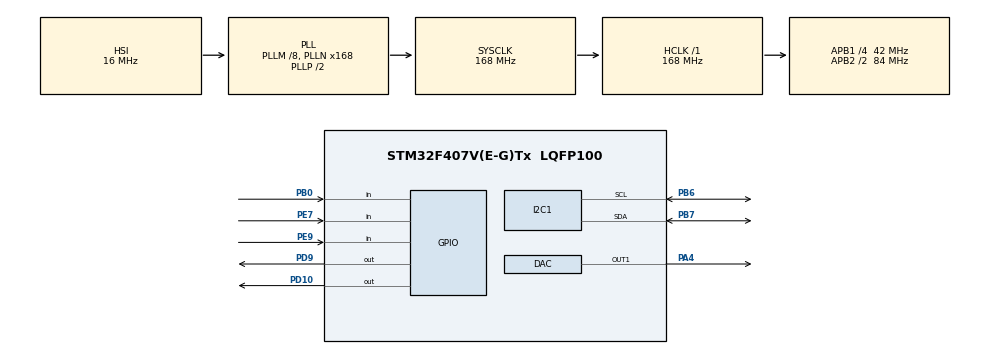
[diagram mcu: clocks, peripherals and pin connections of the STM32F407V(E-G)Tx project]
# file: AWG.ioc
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DAC.DAC_Trigger=DAC_TRIGGER_T2_TRGO
Dma.DAC1.0.Direction=DMA_MEMORY_TO_PERIPH
Dma.DAC1.0.FIFOMode=DMA_FIFOMODE_DISABLE
Dma.DAC1.0.Instance=DMA1_Stream5
Dma.DAC1.0.MemDataAlignment=DMA_MDATAALIGN_HALFWORD
Dma.DAC1.0.MemInc=DMA_MINC_ENABLE
Dma.DAC1.0.Mode=DMA_CIRCULAR
Dma.DAC1.0.PeriphDataAlignment=DMA_PDATAALIGN_HALFWORD
Dma.DAC1.0.PeriphInc=DMA_PINC_DISABLE
Dma.DAC1.0.Priority=DMA_PRIORITY_LOW
Dma.Request0=DAC1
Mcu.Family=STM32F4
Mcu.Name=STM32F407V(E-G)Tx
Mcu.Package=LQFP100
NVIC.DMA1_Stream5_IRQn=true\:0\:0\:false\:false\:true\:false\:true\:true
NVIC.PriorityGroup=NVIC_PRIORITYGROUP_4
PA4.Signal=COMP_DAC1_group
PB0.GPIO_PuPd=GPIO_PULLUP
PB0.Signal=GPIO_Input
PB6.Mode=I2C
PB6.Signal=I2C1_SCL
PB7.Mode=I2C
PB7.Signal=I2C1_SDA
PC14-OSC32_IN.Mode=LSE-External-Oscillator
PC14-OSC32_IN.Signal=RCC_OSC32_IN
PC15-OSC32_OUT.Mode=LSE-External-Oscillator
PC15-OSC32_OUT.Signal=RCC_OSC32_OUT
PD10.GPIO_ModeDefaultOutputPP=GPIO_MODE_OUTPUT_OD
PD10.GPIO_PuPd=GPIO_PULLUP
PD10.Signal=GPIO_Output
PD9.GPIO_ModeDefaultOutputPP=GPIO_MODE_OUTPUT_OD
PD9.GPIO_PuPd=GPIO_PULLUP
PD9.Signal=GPIO_Output
PE7.GPIO_PuPd=GPIO_PULLUP
PE7.Signal=GPIO_Input
PE9.GPIO_PuPd=GPIO_PULLUP
PE9.Signal=GPIO_Input
PH0-OSC_IN.Mode=HSE-External-Oscillator
PH0-OSC_IN.Signal=RCC_OSC_IN
PH1-OSC_OUT.Mode=HSE-External-Oscillator
PH1-OSC_OUT.Signal=RCC_OSC_OUT
ProjectManager.HeapSize=0x200
ProjectManager.StackSize=0x400
ProjectManager.TargetToolchain=MDK-ARM V5.32
RCC.48MHZClocksFreq_Value=84000000
RCC.AHBFreq_Value=168000000
RCC.APB1CLKDivider=RCC_HCLK_DIV4
RCC.APB1Freq_Value=42000000
RCC.APB1TimFreq_Value=84000000
RCC.APB2CLKDivider=RCC_HCLK_DIV2
RCC.APB2Freq_Value=84000000
RCC.APB2TimFreq_Value=168000000
RCC.CortexFreq_Value=168000000
RCC.HCLKFreq_Value=168000000
RCC.HSE_VALUE=8000000
RCC.HSI_VALUE=16000000
RCC.PLLM=8
RCC.PLLN=168
RCC.SYSCLKFreq_VALUE=168000000
RCC.SYSCLKSource=RCC_SYSCLKSOURCE_PLLCLK
RCC.VCOOutputFreq_Value=336000000
SH.COMP_DAC1_group.0=DAC_OUT1,DAC_OUT1
TIM2.Period=6-1
TIM2.Prescaler=7-1
VP_TIM2_VS_ClockSourceINT.Mode=Internal
board=custom

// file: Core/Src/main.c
/* USER CODE BEGIN Header */
/**
  ******************************************************************************
  * @file           : main.c
  * @brief          : Main program body
  ******************************************************************************
  * @attention
  *
  * Copyright (c) 2026 STMicroelectronics.
  * All rights reserved.
  *
  * This software is licensed under terms that can be found in the LICENSE file
  * in the root directory of this software component.
  * If no LICENSE file comes with this software, it is provided AS-IS.
  *
  ******************************************************************************
  */
/* USER CODE END Header */
#include "main.h"
#include "dac.h"
#include "dma.h"
#include "i2c.h"
#include "tim.h"
#include "gpio.h"

/* USER CODE BEGIN Includes */
#include "waveform.h"
#include "key_handler.h"
#include "OLED.h"
#include "delay.h"
/* USER CODE END Includes */

/* USER CODE BEGIN PV */
static uint32_t last_tick; /* Key_Ticks 5ms 节拍 */
/* USER CODE END PV */

void SystemClock_Config(void);

int main(void)
{

  /* MCU Configuration--------------------------------------------------------*/

  /* Reset of all peripherals, Initializes the Flash interface and the Systick. */
  HAL_Init();

  /* Configure the system clock */
  SystemClock_Config();

  /* Initialize all configured peripherals */
  MX_GPIO_Init();
  MX_DMA_Init();
  MX_DAC_Init();
  MX_TIM2_Init();
  MX_I2C1_Init();
  /* USER CODE BEGIN 2 */
  WaveGen_Init();
  WaveGen_Start(WAVE_SINE, 1000); /* 默认输出 1kHz 正弦波 */
  Key_Init();
  Delay_Init();
  last_tick = HAL_GetTick();
  /* USER CODE END 2 */

  /* Infinite loop */
  while (1)
  {

    /* USER CODE BEGIN 3 */
    /* 每 5ms 驱动一次 MultiButton 状态机 */
    if (HAL_GetTick() - last_tick >= 5) {
        last_tick = HAL_GetTick();
        Key_Ticks();
    }

  /* USER CODE END 3 */
}

void SystemClock_Config(void)
{
  RCC_OscInitTypeDef RCC_OscInitStruct = {0};
  RCC_ClkInitTypeDef RCC_ClkInitStruct = {0};

  /** Configure the main internal regulator output voltage
  */
  __HAL_RCC_PWR_CLK_ENABLE();
  __HAL_PWR_VOLTAGESCALING_CONFIG(PWR_REGULATOR_VOLTAGE_SCALE1);

  /** Initializes the RCC Oscillators according to the specified parameters
  * in the RCC_OscInitTypeDef structure.
  */
  RCC_OscInitStruct.OscillatorType = RCC_OSCILLATORTYPE_HSI;
  RCC_OscInitStruct.HSIState = RCC_HSI_ON;
  RCC_OscInitStruct.HSICalibrationValue = RCC_HSICALIBRATION_DEFAULT;
  RCC_OscInitStruct.PLL.PLLState = RCC_PLL_ON;
  RCC_OscInitStruct.PLL.PLLSource = RCC_PLLSOURCE_HSI;
  RCC_OscInitStruct.PLL.PLLM = 8;
  RCC_OscInitStruct.PLL.PLLN = 168;
  RCC_OscInitStruct.PLL.PLLP = RCC_PLLP_DIV2;
  RCC_OscInitStruct.PLL.PLLQ = 4;
  if (HAL_RCC_OscConfig(&RCC_OscInitStruct) != HAL_OK)
  {
    Error_Handler();
  }

  /** Initializes the CPU, AHB and APB buses clocks
  */
  RCC_ClkInitStruct.ClockType = RCC_CLOCKTYPE_HCLK|RCC_CLOCKTYPE_SYSCLK
                              |RCC_CLOCKTYPE_PCLK1|RCC_CLOCKTYPE_PCLK2;
  RCC_ClkInitStruct.SYSCLKSource = RCC_SYSCLKSOURCE_PLLCLK;
  RCC_ClkInitStruct.AHBCLKDivider = RCC_SYSCLK_DIV1;
  RCC_ClkInitStruct.APB1CLKDivider = RCC_HCLK_DIV4;
  RCC_ClkInitStruct.APB2CLKDivider = RCC_HCLK_DIV2;

  if (HAL_RCC_ClockConfig(&RCC_ClkInitStruct, FLASH_LATENCY_5) != HAL_OK)
  {
    Error_Handler();
  }
}

void Error_Handler(void)
{
  __disable_irq();
  while (1)
  {
  }
}
